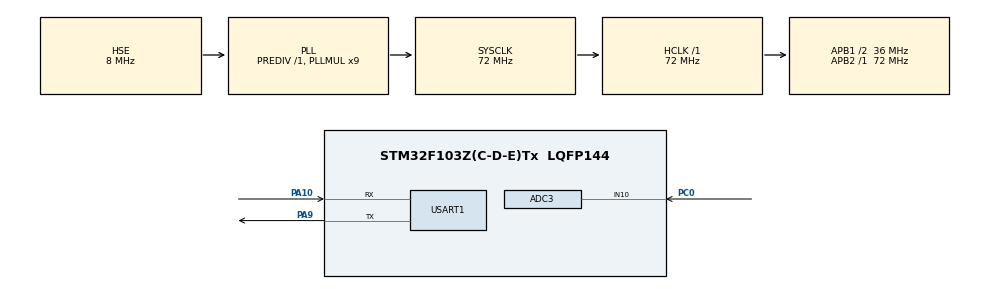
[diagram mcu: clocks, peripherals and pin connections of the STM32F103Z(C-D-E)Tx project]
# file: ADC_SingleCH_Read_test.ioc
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ADC3.Channel-1\#ChannelRegularConversion=ADC_CHANNEL_10
ADC3.NbrOfConversionFlag=1
ADC3.Rank-1\#ChannelRegularConversion=1
ADC3.SamplingTime-1\#ChannelRegularConversion=ADC_SAMPLETIME_1CYCLE_5
Mcu.Family=STM32F1
Mcu.Name=STM32F103Z(C-D-E)Tx
Mcu.Package=LQFP144
NVIC.ADC3_IRQn=true\:0\:0\:false\:false\:true\:true\:true\:true
NVIC.PriorityGroup=NVIC_PRIORITYGROUP_4
OSC_IN.Mode=HSE-External-Oscillator
OSC_IN.Signal=RCC_OSC_IN
OSC_OUT.Mode=HSE-External-Oscillator
OSC_OUT.Signal=RCC_OSC_OUT
PA10.Mode=Asynchronous
PA10.Signal=USART1_RX
PA13.Mode=Serial_Wire
PA13.Signal=SYS_JTMS-SWDIO
PA14.Mode=Serial_Wire
PA14.Signal=SYS_JTCK-SWCLK
PA9.Mode=Asynchronous
PA9.Signal=USART1_TX
PC0.Signal=ADCx_IN10
ProjectManager.HeapSize=0x200
ProjectManager.StackSize=0x400
ProjectManager.TargetToolchain=MDK-ARM V5.32
RCC.ADCPresc=RCC_ADCPCLK2_DIV6
RCC.AHBFreq_Value=72000000
RCC.APB1CLKDivider=RCC_HCLK_DIV2
RCC.APB1Freq_Value=36000000
RCC.APB1TimFreq_Value=72000000
RCC.APB2Freq_Value=72000000
RCC.APB2TimFreq_Value=72000000
RCC.HCLKFreq_Value=72000000
RCC.PLLMUL=RCC_PLL_MUL9
RCC.PLLSourceVirtual=RCC_PLLSOURCE_HSE
RCC.SYSCLKFreq_VALUE=72000000
RCC.SYSCLKSource=RCC_SYSCLKSOURCE_PLLCLK
RCC.USBFreq_Value=72000000
SH.ADCx_IN10.0=ADC3_IN10,IN10
USART1.Parity=PARITY_ODD
USART1.VirtualMode=VM_ASYNC
USART1.WordLength=WORDLENGTH_9B
board=custom

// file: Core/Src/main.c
/* USER CODE BEGIN Header */
/**
  ******************************************************************************
  * @file           : main.c
  * @brief          : Main program body
  ******************************************************************************
  * @attention
  *
  * Copyright (c) 2026 STMicroelectronics.
  * All rights reserved.
  *
  * This software is licensed under terms that can be found in the LICENSE file
  * in the root directory of this software component.
  * If no LICENSE file comes with this software, it is provided AS-IS.
  *
  ******************************************************************************
  */
/* USER CODE END Header */
#include "main.h"

/* USER CODE BEGIN Includes */
#include "BSP_Usart_Redir.h"
/* USER CODE END Includes */

ADC_HandleTypeDef hadc3;

UART_HandleTypeDef huart1;

void SystemClock_Config(void);
static void MX_GPIO_Init(void);
static void MX_ADC3_Init(void);
static void MX_USART1_UART_Init(void);
/* USER CODE BEGIN PFP */
static uint32_t ADC_Code_To_Voltage(uint32_t value);
0-65 static void ADC_Read_Block(ADC_HandleTypeDef* hadc, uint32_t* value);
/* USER CODE END PFP */

int main(void)
{

  /* MCU Configuration--------------------------------------------------------*/

  /* Reset of all peripherals, Initializes the Flash interface and the Systick. */
  HAL_Init();

  /* USER CODE BEGIN Init */
  BSP_Usart_Init(&huart1);
  /* USER CODE END Init */

  /* Configure the system clock */
  SystemClock_Config();

  /* Initialize all configured peripherals */
  MX_GPIO_Init();
  MX_ADC3_Init();
  MX_USART1_UART_Init();
  /* USER CODE BEGIN 2 */

  uint32_t value = 0;

  //ADC校准
  HAL_ADCEx_Calibration_Start(&hadc3);

  /* USER CODE END 2 */

  /* Infinite loop */
  /* USER CODE BEGIN WHILE */
  while (1)
  {
    ADC_Read_Block(&hadc3, &value);
    printf("ADC3: %d\n", value);
    HAL_Delay(1000);
    /* USER CODE END WHILE */

  }
}

void SystemClock_Config(void)
{
  RCC_OscInitTypeDef RCC_OscInitStruct = {0};
  RCC_ClkInitTypeDef RCC_ClkInitStruct = {0};
  RCC_PeriphCLKInitTypeDef PeriphClkInit = {0};

  /** Initializes the RCC Oscillators according to the specified parameters
  * in the RCC_OscInitTypeDef structure.
  */
  RCC_OscInitStruct.OscillatorType = RCC_OSCILLATORTYPE_HSE;
  RCC_OscInitStruct.HSEState = RCC_HSE_ON;
  RCC_OscInitStruct.HSEPredivValue = RCC_HSE_PREDIV_DIV1;
  RCC_OscInitStruct.HSIState = RCC_HSI_ON;
  RCC_OscInitStruct.PLL.PLLState = RCC_PLL_ON;
  RCC_OscInitStruct.PLL.PLLSource = RCC_PLLSOURCE_HSE;
  RCC_OscInitStruct.PLL.PLLMUL = RCC_PLL_MUL9;
  if (HAL_RCC_OscConfig(&RCC_OscInitStruct) != HAL_OK)
  {
    Error_Handler();
  }

  /** Initializes the CPU, AHB and APB buses clocks
  */
  RCC_ClkInitStruct.ClockType = RCC_CLOCKTYPE_HCLK|RCC_CLOCKTYPE_SYSCLK
                              |RCC_CLOCKTYPE_PCLK1|RCC_CLOCKTYPE_PCLK2;
  RCC_ClkInitStruct.SYSCLKSource = RCC_SYSCLKSOURCE_PLLCLK;
  RCC_ClkInitStruct.AHBCLKDivider = RCC_SYSCLK_DIV1;
  RCC_ClkInitStruct.APB1CLKDivider = RCC_HCLK_DIV2;
  RCC_ClkInitStruct.APB2CLKDivider = RCC_HCLK_DIV1;

  if (HAL_RCC_ClockConfig(&RCC_ClkInitStruct, FLASH_LATENCY_2) != HAL_OK)
  {
    Error_Handler();
  }
  PeriphClkInit.PeriphClockSelection = RCC_PERIPHCLK_ADC;
  PeriphClkInit.AdcClockSelection = RCC_ADCPCLK2_DIV6;
  if (HAL_RCCEx_PeriphCLKConfig(&PeriphClkInit) != HAL_OK)
  {
    Error_Handler();
  }
}

static void MX_ADC3_Init(void)
{

  ADC_ChannelConfTypeDef sConfig = {0};

  /** Common config
  */
  hadc3.Instance = ADC3;
  hadc3.Init.ScanConvMode = ADC_SCAN_DISABLE;
  hadc3.Init.ContinuousConvMode = DISABLE;
  hadc3.Init.DiscontinuousConvMode = DISABLE;
  hadc3.Init.ExternalTrigConv = ADC_SOFTWARE_START;
  hadc3.Init.DataAlign = ADC_DATAALIGN_RIGHT;
  hadc3.Init.NbrOfConversion = 1;
  if (HAL_ADC_Init(&hadc3) != HAL_OK)
  {
    Error_Handler();
  }

  /** Configure Regular Channel
  */
  sConfig.Channel = ADC_CHANNEL_10;
  sConfig.Rank = ADC_REGULAR_RANK_1;
  sConfig.SamplingTime = ADC_SAMPLETIME_1CYCLE_5;
  if (HAL_ADC_ConfigChannel(&hadc3, &sConfig) != HAL_OK)
  {
    Error_Handler();
  }

}

static void MX_USART1_UART_Init(void)
{

  huart1.Instance = USART1;
  huart1.Init.BaudRate = 115200;
  huart1.Init.WordLength = UART_WORDLENGTH_9B;
  huart1.Init.StopBits = UART_STOPBITS_1;
  huart1.Init.Parity = UART_PARITY_ODD;
  huart1.Init.Mode = UART_MODE_TX_RX;
  huart1.Init.HwFlowCtl = UART_HWCONTROL_NONE;
  huart1.Init.OverSampling = UART_OVERSAMPLING_16;
  if (HAL_UART_Init(&huart1) != HAL_OK)
  {
    Error_Handler();
  }

}

static void MX_GPIO_Init(void)
{

  /* GPIO Ports Clock Enable */
  __HAL_RCC_GPIOC_CLK_ENABLE();
  __HAL_RCC_GPIOA_CLK_ENABLE();

}

/* USER CODE BEGIN 4 */

static void ADC_Read_Block(ADC_HandleTypeDef* hadc, uint32_t* value)
{
  //ADC使能并开启转化
  if (HAL_ADC_Start(hadc) != HAL_OK) Error_Handler();

  //等待ADC转还完成
  if (HAL_ADC_PollForConversion(hadc, 100) != HAL_OK) Error_Handler();

  //获取ADC转化的结果
  *value = HAL_ADC_GetValue(hadc);

  //关闭ADC
  HAL_ADC_Stop(hadc);
}

static uint32_t ADC_Code_To_Voltage(uint32_t value)
{
  return (value * 3.3f) / 4096.0f;
}

/* USER CODE END 4 */

void Error_Handler(void)
{
  __disable_irq();
  while (1)
  {
  }
}
